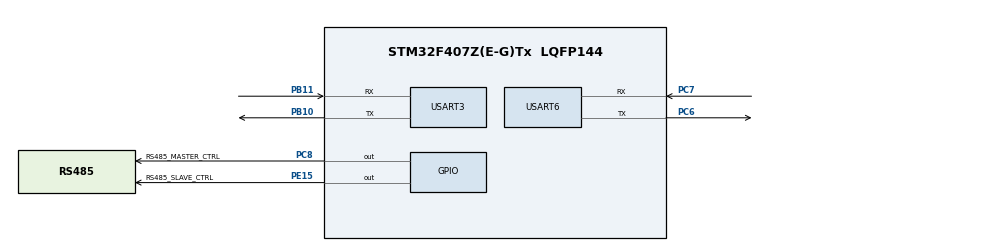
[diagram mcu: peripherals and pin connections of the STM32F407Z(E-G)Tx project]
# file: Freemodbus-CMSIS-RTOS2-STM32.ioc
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FREERTOS.Tasks01=defaultTask,24,128,StartDefaultTask,Default,NULL,Dynamic,NULL,NULL;MBMaster,24,1024,MBMasterPollTask,Default,NULL,Dynamic,NULL,NULL;MBSlave,24,1024,MBSlavePollTask,Default,NULL,Dynamic,NULL,NULL
FREERTOS.configENABLE_FPU=1
FREERTOS.configTOTAL_HEAP_SIZE=32768
Mcu.Family=STM32F4
Mcu.Name=STM32F407Z(E-G)Tx
Mcu.Package=LQFP144
NVIC.PriorityGroup=NVIC_PRIORITYGROUP_4
NVIC.TIM8_TRG_COM_TIM14_IRQn=true\:15\:0\:false\:false\:true\:false\:false\:true\:true
NVIC.TimeBase=TIM8_TRG_COM_TIM14_IRQn
NVIC.TimeBaseIP=TIM14
NVIC.USART3_IRQn=true\:5\:0\:false\:false\:true\:true\:true\:true\:true
NVIC.USART6_IRQn=true\:5\:0\:false\:false\:true\:true\:true\:true\:true
PA13.Mode=Serial_Wire
PA13.Signal=SYS_JTMS-SWDIO
PA14.Mode=Serial_Wire
PA14.Signal=SYS_JTCK-SWCLK
PB10.Mode=Asynchronous
PB10.Signal=USART3_TX
PB11.Mode=Asynchronous
PB11.Signal=USART3_RX
PC6.Mode=Asynchronous
PC6.Signal=USART6_TX
PC7.Mode=Asynchronous
PC7.Signal=USART6_RX
PC8.GPIO_Label=RS485_MASTER_CTRL
PC8.Signal=GPIO_Output
PE15.GPIO_Label=RS485_SLAVE_CTRL
PE15.Signal=GPIO_Output
ProjectManager.HeapSize=0x200
ProjectManager.StackSize=0x400
ProjectManager.TargetToolchain=Makefile
RCC.48MHZClocksFreq_Value=84000000
RCC.AHBFreq_Value=168000000
RCC.APB1CLKDivider=RCC_HCLK_DIV4
RCC.APB1Freq_Value=42000000
RCC.APB1TimFreq_Value=84000000
RCC.APB2CLKDivider=RCC_HCLK_DIV2
RCC.APB2Freq_Value=84000000
RCC.APB2TimFreq_Value=168000000
RCC.CortexFreq_Value=168000000
RCC.HCLKFreq_Value=168000000
RCC.HSE_VALUE=25000000
RCC.HSI_VALUE=16000000
RCC.LSE_VALUE=32768
RCC.PLLM=8
RCC.PLLN=168
RCC.SYSCLKFreq_VALUE=168000000
RCC.SYSCLKSource=RCC_SYSCLKSOURCE_PLLCLK
RCC.VCOOutputFreq_Value=336000000
USART3.VirtualMode=VM_ASYNC
USART6.VirtualMode=VM_ASYNC
VP_FREERTOS_VS_CMSIS_V2.Mode=CMSIS_V2
VP_SYS_VS_tim14.Mode=TIM14
board=custom

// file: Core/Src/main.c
/* USER CODE BEGIN Header */
/**
  ******************************************************************************
  * @file           : main.c
  * @brief          : Main program body
  ******************************************************************************
  * @attention
  *
  * Copyright (c) 2022 STMicroelectronics.
  * All rights reserved.
  *
  * This software is licensed under terms that can be found in the LICENSE file
  * in the root directory of this software component.
  * If no LICENSE file comes with this software, it is provided AS-IS.
  *
  ******************************************************************************
  */
/* USER CODE END Header */
#include "main.h"
#include "cmsis_os.h"

/* USER CODE BEGIN Includes */
#include "user_mb_app.h"

/* USER CODE END Includes */

 UART_HandleTypeDef huart3;
UART_HandleTypeDef huart6;

/* Definitions for defaultTask */
osThreadId_t defaultTaskHandle;
const osThreadAttr_t defaultTask_attributes = {
  .name = "defaultTask",
  .stack_size = 128 * 4,
  .priority = (osPriority_t) osPriorityNormal,
};
/* Definitions for MBMaster */
osThreadId_t MBMasterHandle;
const osThreadAttr_t MBMaster_attributes = {
  .name = "MBMaster",
  .stack_size = 1024 * 4,
  .priority = (osPriority_t) osPriorityNormal,
};
/* Definitions for MBSlave */
osThreadId_t MBSlaveHandle;
const osThreadAttr_t MBSlave_attributes = {
  .name = "MBSlave",
  .stack_size = 1024 * 4,
  .priority = (osPriority_t) osPriorityNormal,
};

void SystemClock_Config(void);
static void MX_GPIO_Init(void);
static void MX_USART3_UART_Init(void);
static void MX_USART6_UART_Init(void);
void StartDefaultTask(void *argument);
void MBMasterPollTask(void *argument);
void MBSlavePollTask(void *argument);

int main(void)
{

  /* MCU Configuration--------------------------------------------------------*/

  /* Reset of all peripherals, Initializes the Flash interface and the Systick. */
  HAL_Init();

  /* Configure the system clock */
  SystemClock_Config();

  /* Initialize all configured peripherals */
  MX_GPIO_Init();
  MX_USART3_UART_Init();
  MX_USART6_UART_Init();

  /* Init scheduler */
  osKernelInitialize();

  /* Create the thread(s) */
  /* creation of defaultTask */
  defaultTaskHandle = osThreadNew(StartDefaultTask, NULL, &defaultTask_attributes);

  /* creation of MBMaster */
  MBMasterHandle = osThreadNew(MBMasterPollTask, NULL, &MBMaster_attributes);

  /* creation of MBSlave */
  MBSlaveHandle = osThreadNew(MBSlavePollTask, NULL, &MBSlave_attributes);

  /* Start scheduler */
  osKernelStart();

  /* We should never get here as control is now taken by the scheduler */
  /* Infinite loop */
  while (1)
  {

  }
}

void SystemClock_Config(void)
{
  LL_FLASH_SetLatency(LL_FLASH_LATENCY_5);
  while(LL_FLASH_GetLatency()!= LL_FLASH_LATENCY_5)
  {
  }
  LL_PWR_SetRegulVoltageScaling(LL_PWR_REGU_VOLTAGE_SCALE1);
  LL_RCC_HSI_SetCalibTrimming(16);
  LL_RCC_HSI_Enable();

   /* Wait till HSI is ready */
  while(LL_RCC_HSI_IsReady() != 1)
  {

  }
  LL_RCC_PLL_ConfigDomain_SYS(LL_RCC_PLLSOURCE_HSI, LL_RCC_PLLM_DIV_8, 168, LL_RCC_PLLP_DIV_2);
  LL_RCC_PLL_Enable();

   /* Wait till PLL is ready */
  while(LL_RCC_PLL_IsReady() != 1)
  {

  }
  LL_RCC_SetAHBPrescaler(LL_RCC_SYSCLK_DIV_1);
  LL_RCC_SetAPB1Prescaler(LL_RCC_APB1_DIV_4);
  LL_RCC_SetAPB2Prescaler(LL_RCC_APB2_DIV_2);
  LL_RCC_SetSysClkSource(LL_RCC_SYS_CLKSOURCE_PLL);

   /* Wait till System clock is ready */
  while(LL_RCC_GetSysClkSource() != LL_RCC_SYS_CLKSOURCE_STATUS_PLL)
  {

  }
  LL_SetSystemCoreClock(168000000);

   /* Update the time base */
  if (HAL_InitTick (TICK_INT_PRIORITY) != HAL_OK)
  {
    Error_Handler();
  }
}

static void MX_USART3_UART_Init(void)
{

  huart3.Instance = USART3;
  huart3.Init.BaudRate = 115200;
  huart3.Init.WordLength = UART_WORDLENGTH_8B;
  huart3.Init.StopBits = UART_STOPBITS_1;
  huart3.Init.Parity = UART_PARITY_NONE;
  huart3.Init.Mode = UART_MODE_TX_RX;
  huart3.Init.HwFlowCtl = UART_HWCONTROL_NONE;
  huart3.Init.OverSampling = UART_OVERSAMPLING_16;
  if (HAL_UART_Init(&huart3) != HAL_OK)
  {
    Error_Handler();
  }

}

static void MX_USART6_UART_Init(void)
{

  huart6.Instance = USART6;
  huart6.Init.BaudRate = 115200;
  huart6.Init.WordLength = UART_WORDLENGTH_8B;
  huart6.Init.StopBits = UART_STOPBITS_1;
  huart6.Init.Parity = UART_PARITY_NONE;
  huart6.Init.Mode = UART_MODE_TX_RX;
  huart6.Init.HwFlowCtl = UART_HWCONTROL_NONE;
  huart6.Init.OverSampling = UART_OVERSAMPLING_16;
  if (HAL_UART_Init(&huart6) != HAL_OK)
  {
    Error_Handler();
  }

}

static void MX_GPIO_Init(void)
{
  LL_GPIO_InitTypeDef GPIO_InitStruct = {0};

  /* GPIO Ports Clock Enable */
  LL_AHB1_GRP1_EnableClock(LL_AHB1_GRP1_PERIPH_GPIOE);
  LL_AHB1_GRP1_EnableClock(LL_AHB1_GRP1_PERIPH_GPIOB);
  LL_AHB1_GRP1_EnableClock(LL_AHB1_GRP1_PERIPH_GPIOC);
  LL_AHB1_GRP1_EnableClock(LL_AHB1_GRP1_PERIPH_GPIOA);

  /**/
  LL_GPIO_ResetOutputPin(RS485_SLAVE_CTRL_GPIO_Port, RS485_SLAVE_CTRL_Pin);

  /**/
  LL_GPIO_ResetOutputPin(RS485_MASTER_CTRL_GPIO_Port, RS485_MASTER_CTRL_Pin);

  /**/
  GPIO_InitStruct.Pin = RS485_SLAVE_CTRL_Pin;
  GPIO_InitStruct.Mode = LL_GPIO_MODE_OUTPUT;
  GPIO_InitStruct.Speed = LL_GPIO_SPEED_FREQ_LOW;
  GPIO_InitStruct.OutputType = LL_GPIO_OUTPUT_PUSHPULL;
  GPIO_InitStruct.Pull = LL_GPIO_PULL_NO;
  LL_GPIO_Init(RS485_SLAVE_CTRL_GPIO_Port, &GPIO_InitStruct);

  /**/
  GPIO_InitStruct.Pin = RS485_MASTER_CTRL_Pin;
  GPIO_InitStruct.Mode = LL_GPIO_MODE_OUTPUT;
  GPIO_InitStruct.Speed = LL_GPIO_SPEED_FREQ_LOW;
  GPIO_InitStruct.OutputType = LL_GPIO_OUTPUT_PUSHPULL;
  GPIO_InitStruct.Pull = LL_GPIO_PULL_NO;
  LL_GPIO_Init(RS485_MASTER_CTRL_GPIO_Port, &GPIO_InitStruct);

}

void StartDefaultTask(void *argument)
{
  for(;;)
  {
    osDelay(1);
  }
}

void MBMasterPollTask(void *argument)
{
  /* USER CODE BEGIN MBMasterPollTask */
  eMBMasterInit(MB_RTU, 6, 9600, MB_PAR_NONE);
  eMBMasterEnable();
  /* Infinite loop */
  for(;;)
  {
    eMBMasterPoll();
  }
  /* USER CODE END MBMasterPollTask */
}

void MBSlavePollTask(void *argument)
{
  /* USER CODE BEGIN MBSlavePollTask */
  eMBInit(MB_RTU, 0x01, 3, 9600, MB_PAR_NONE);
  eMBEnable();
  /* Infinite loop */
  for(;;)
  {
    eMBPoll();
  }
  /* USER CODE END MBSlavePollTask */
}

void HAL_TIM_PeriodElapsedCallback(TIM_HandleTypeDef *htim)
{
  if (htim->Instance == TIM14) {
    HAL_IncTick();
  }
}

void Error_Handler(void)
{
  __disable_irq();
  while (1)
  {
  }
}
